# MMCSD8_MMC_CTLCFG_0FA00000h register map
Vendor: Texas Instruments
Registers are 16-bit, read-write, reset 0x0 unless marked. A register's access mark holds for its fields unless they carry their own. Offsets are as the file gives them; [hi:lo] are bit positions; {n}, {i} and the like mark numbered series; 'fields as' and 'values as' point back to an identical list.

## mmc_ctlcfg (part 3 of 4)
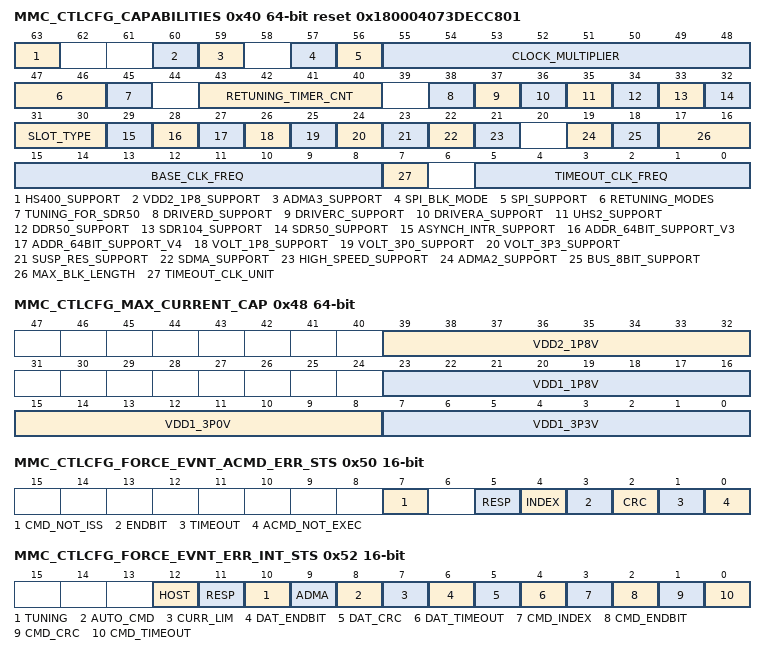
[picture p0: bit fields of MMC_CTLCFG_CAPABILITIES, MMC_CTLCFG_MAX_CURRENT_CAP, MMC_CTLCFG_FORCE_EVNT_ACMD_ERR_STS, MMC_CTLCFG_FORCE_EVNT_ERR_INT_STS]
0x40 MMC_CTLCFG_CAPABILITIES 64-bit ro reset 0x180004073DECC801 — This register provides the HD with information specific to the HC implementation. The HC may implement these values as fixed or loaded from flash memory during power on initialization.
  [63] HS400_SUPPORT — 1 HS400 is Supported 0 HS400 is Not Supported 0 HS400 Mode is not Supported1 HS400 Mode is Supported
  [60] VDD2_1P8_SUPPORT — This field indicates that support of VDD2 on Host system. 0 1.8V VDD2 is not Supported1 1.8V VDD2 is Supported
  [59] ADMA3_SUPPORT — This field indicates that support of ADMA3 on Host Controller. 0 ADMA3 is not Supported1 ADMA3 is Supported
  [57] SPI_BLK_MODE — This field indicates whether SPI Block Mode is supported or not. 0 SPI Block Mode is not Supported1 SPI Block Mode is Supported
  [56] SPI_SUPPORT — This field indicates whether SPI Mode is supported or not. 0 SPI Mode is not Supported1 SPI Mode is Supported
  [55:48] CLOCK_MULTIPLIER — This field indicates clock multiplier value of programmable clock generator. Refer to Clock Control register. Setting 00h means that Host Controller does not support programmable clock generator. 'FF' Clock Multiplier M = 256 --------- '02' Clock Multiplier M = 3 '01' Clock Multiplier M = 2 '00' Clock Multiplier is Not Supported. Reset Source: vbus_amod_g_rst_n
  [47:46] RETUNING_MODES — This field defines the re-tuning capability of a Host Controller and how to manage the data transfer length and a Re-Tuning Timer by the Host Driver. '00' Mode 1 '01' Mode 2 '10' Mode 3 '11' Reserved.There are two re-tuning timings:Re-Tuning Request and expiration of a Re-Tuning Timer. By receiving either timing, the Host Driver executes the re-tuning procedure just before a next command issue. 0 Mode 11 Mode 22 Mode 33 Reserved
  [45] TUNING_FOR_SDR50 — If this bit is set to 1, this Host Controller requires tuning to operate SDR50. [Tuning is always required to operate SDR104]. '0' '1' 0 SDR50 does not require tuning1 SDR50 requires tuning
  [43:40] RETUNING_TIMER_CNT — This field indicates an initial value of the Re-Tuning Timer for Re-Tuning Mode 1 to 3. 0h - Get information via other source 1h = 1 seconds 2h = 2 seconds 3h = 4 seconds 4h = 8 seconds ------ n = 2[n-1] seconds ------ Bh = 1024 seconds Fh - Ch = Reserved Reset Source: vbus_amod_g_rst_n
  [38] DRIVERD_SUPPORT — This bit indicates support of Driver Type D for 1.8 Signaling. '0' Driver Type D is Not supported, '1' Driver Type D is supported 0 Driver Type D is not Supported1 Driver Type D is Supported
  [37] DRIVERC_SUPPORT — This bit indicates support of Driver Type C for 1.8 Signaling. '0' Driver Type C is Not supported, '1' Driver Type C is supported 0 Driver Type C is not Supported1 Driver Type C is Supported
  [36] DRIVERA_SUPPORT — This bit indicates support of Driver Type A for 1.8 Signaling. '0' Driver Type A is Not supported, '1' Driver Type A is supported 0 Driver Type A is not Supported1 Driver Type A is Supported
  [35] UHS2_SUPPORT — This bit indicates whether Host controller supports UHS-II. If this bit is set to 1, 1.8V VDD2 Support shall be set to 1 [Host Sys- tem shall support VDD2 power supply]. 1 UHS-II is Supported 0 UHS-II is Not Supported 0 UHS-II is not Supported1 UHS-II is Supported
  [34] DDR50_SUPPORT — This bit indicates whether DDR50 is supported or not. 0 DDR50 is not Supported1 DDR50 is Supported
  [33] SDR104_SUPPORT — This bit indicates whether SDR104 is supported or not.SDR104 requires tuning. 0 SDR104 is not Supported1 SDR104 is Supported
  [32] SDR50_SUPPORT — If SDR104 is supported, this bit shall be set to 1. Bit 40 indicates whether SDR50 requires tuning or not. 0 SDR50 is not Supported1 SDR50 is Supported
  [31:30] SLOT_TYPE — This field indicates usage of a slot by a specific Host System. [A host controller register set is defined perslot.] Embedded slot for one device [01b] means that only one non-removable device is connected to a SD bus slot. Shared Bus Slot [10b] can be set if Host Controller supports Shared Bus Control register. The Standard Host Driver controls only a removable card or one embedded device is connected to a SD bus slot. If a slot is configured for shared bus [10b], the Standard Host Driver does not control embedded devices connected to a shared bus. Shared bus slot is controlled by a specific host driver developed by a Host System. 0 Removeable Card Slot1 Embedded Slot for One Device2 Shared Bus Slot (SD Mode)3 Reserved
  [29] ASYNCH_INTR_SUPPORT — Refer to SDIO Specification Version 3.00 about asynchronous interrupt. 0 Asynchronous Interrupt not Supported1 Asynchronous Interrupt Supported
  [28] ADDR_64BIT_SUPPORT_V3 — IMeaning of this bit is different depends on Versions [Refer to Table 2-35 for more details]. Host Controller Version 3.00 and Ver4.10 use this bit as 64-bit System Address support for V3 mode. Host Con- troller Version 4.00 uses this bit as 64-bit System Address support for both V3 and V4 modes. SDMA cannot be used in 64-bit Address-ing in Version 3 mode. If this bit is set to 1, 64-bit ADMA2 with using 96-bit Descriptor may be enabled as follows: In case of Host Controller Version 3, 64-bit ADMA2 is enabled by DMA Select =11b in the Host Control 1 register. In case of Host Controller Version 4, 64-bitADMA2 for Version 3 is enabled by setting Host Version 4 Enable =0 and DMA Select = 11b. 1 - 64-bit System Address for V3 is Supported 0 - 64-bit System Address for V3 is not Supported 0 64-bit System Address for V3 is not Supported1 64-bit System Address for V3 is Supported
  [27] ADDR_64BIT_SUPPORT_V4 — This bit is added from Version 4.10. Set-ting 1 to this bit indicates that the Host Controller supports 64-bit System Addressing of Version 4 mode [Refer to Table 2-35 for the summary of 64-bit sys-tem address support].. When this bit is set to 1, full or a part of 64-bit address should be used to decode Host Controller Registers so that Host Controller Registers can be placed above system memory area. 64-bit address decode of Host Controller Registers is effective regardless of setting to 64bit Addressing in Host Control 2. If this bit is set to 1, 64-bit DMA Address-ing for Version 4 is enabled by setting Host Version 4 Enable =1, 64-bit Address-ing =1 in the Host Control 2 register.SDMA can be used and ADMA2 uses 128-bit Descriptor. 0 64-bit System Address for V4 is not Supported1 64-bit System Address for V4 is Supported
  [26] VOLT_1P8_SUPPORT — This bit indicates whether the HC supports 1.8V. 0 1.8V Not Supported1 1.8V Supported
  [25] VOLT_3P0_SUPPORT — This bit indicates whether the HC supports 3.0V. 0 3.0V Not Supported1 3.3V Supported
  [24] VOLT_3P3_SUPPORT — This bit indicates whether the HC supports 3.3V. 0 3.3V Not Supported1 3.3V Supported
  [23] SUSP_RES_SUPPORT — This bit indicates whether the HC supports Suspend / Resume functionality. If this bit is 0, the Suspend and Resume mechanism are not supported and the HD shall not issue either Suspend / Resume commands. 0 Suspend and Resume mechanism Not Supported1 Suspend and Resume mechanism Supported
  [22] SDMA_SUPPORT — This bit indicates whether the HC is capable of using DMA to transfer data between system memory and the HC directly.Version 4.10 Host Controller shall support SDMA if ADMA2 is supported. 0 SDMA Not Supported1 SDMA Supported
  [21] HIGH_SPEED_SUPPORT — This bit indicates whether the HC and the Host System support High Speed mode and they can supply SD Clock frequency from 25Mhz to 50 Mhz [for SD]/ 20MHz to 52MHz [for MMC]. 0 High Speed Not Supported1 High Speed Supported
  [19] ADMA2_SUPPORT — '0' ADMA2 Not Supported '1' ADMA2 Supported 0 ADMA2 Not Supported1 ADMA2 Supported
  [18] BUS_8BIT_SUPPORT — This bit indicates whether the Host Controller is capable of using 8-bit bus width mode. This bit is not effective when Slot Type is set to 10b. In this case, refer to Bus Width Preset in the Shared Bus resister. 0 Extended Media Bus Not Supported1 Extended Media Bus Supported
  [17:16] MAX_BLK_LENGTH — This value indicates the maximum block size that the HD can read and write to the buffer in the HC. The buffer shall transfer this block size without wait cycles. Three sizes can be defined as indicated below. 0 512 byte1 1024 byte2 2048 byte3 4096 byte
  [15:8] BASE_CLK_FREQ — [1]6-bit Base Clock Frequency: This mode is supported by the Host Controller Version 1.00 and 2.00. Upper 2-bit is not effective and always 0. Unit values are 1MHz. The supported clock range is 10MHz to 63MHz. '11xx xxxxb' Not Supported '0011 1111b' 63MHz '0000 0010b' 2MHz '0000 0001b' 1MHz '0000 0000b'Get Information via another method [2]8-bit Base Clock Frequency: This mode is supported by the Host Controller Version 3.00.Unit values are 1MHz. The supported clock range is 10MHz to 255MHz. 'FFh' 255MHz '02h' 2MHz '01h' 1MHz '00h' Get Information via another method.If the real frequency is 16.5MHz, the lager value shall be set 0001 0001b [17MHz] because the Host Driver use this value to calculate the clock divider value [Refer to the SDCLK Frequency Select in the Clock Control register.] and it shall not exceed upper limit of the SD Clock frequency. If these bits are all 0, the Host System has to get information via another method. Reset Source: vbus_amod_g_rst_n
  [7] TIMEOUT_CLK_UNIT — This bit shows the unit of base clock frequency used to detect Data Timeout Error. 0 KHz1 MHz
  [5:0] TIMEOUT_CLK_FREQ — This bit shows the base clock frequency used to detect Data Timeout Error. '000000' Get Information via another method, 'not 0' 1KHz to 63KHz/1MHz to 63MHz Reset Source: vbus_amod_g_rst_n
0x48 MMC_CTLCFG_MAX_CURRENT_CAP 64-bit ro — This register indicates maximum current capability for each voltage
  [39:32] VDD2_1P8V — Maximum Current for 1.8V VDD2 Reset Source: vbus_amod_g_rst_n
  [23:16] VDD1_1P8V — Maximum Current for 1.8V VDD1 Reset Source: vbus_amod_g_rst_n
  [15:8] VDD1_3P0V — Maximum Current for 3.0V VDD1 Reset Source: vbus_amod_g_rst_n
  [7:0] VDD1_3P3V — Maximum Current for 3.3V VDD1 Reset Source: vbus_amod_g_rst_n
0x50 MMC_CTLCFG_FORCE_EVNT_ACMD_ERR_STS wo — This register is not physically implemented, rather it is an address where Auto CMD Error Status register can be written. Writing 1 : set each bit of the Auto CMD12 Error Status Register Writing 0 : no effect.
  [7] CMD_NOT_ISS — Force Event for Command Not Issued by AUTO CMD12 Error. 0 No Interrupt1 Interrupt is generated
  [5] RESP — Force Event for AUTO CMD Response Error.. 0 No Interrupt1 Interrupt is generated
  [4] INDEX — Force Event for AUTO CMD Index Error.. 0 No Interrupt1 Interrupt is generated
  [3] ENDBIT — Force Event for AUTO CMD End Bit Error. 0 No Interrupt1 Interrupt is generated
  [2] CRC — Force Event for AUTO CMD Timeout Error. 0 No Interrupt1 Interrupt is generated
  [1] TIMEOUT — Force Event for AUTO CMD Timeout Error. 0 No Interrupt1 Interrupt is generated
  [0] ACMD_NOT_EXEC — Force Event for AUTO CMD12 Not Executed. 0 No Interrupt1 Interrupt is generated
0x52 MMC_CTLCFG_FORCE_EVNT_ERR_INT_STS wo — This register is not physically implemented, rather it is an address where Error Interrupt Status register can be written.
  [12] HOST — Force Event for Host Error 0 No Interrupt1 Interrupt is generated
  [11] RESP — Force Event for Response Error 0 No Interrupt1 Interrupt is generated
  [10] TUNING — Force Event for Tuning Error. 0 No Interrupt1 Interrupt is generated
  [9] ADMA — Force Event for ADMA Error. 0 No Interrupt1 Interrupt is generated
  [8] AUTO_CMD — Force Event for Auto CMD Error. 0 No Interrupt1 Interrupt is generated
  [7] CURR_LIM — Force Event for Current Limit Error. 0 No Interrupt1 Interrupt is generated
  [6] DAT_ENDBIT — Force Event for Data End Bit Error. 0 No Interrupt1 Interrupt is generated
  [5] DAT_CRC — Force Event for Data CRC Error. 0 No Interrupt1 Interrupt is generated
  [4] DAT_TIMEOUT — Force Event for Data Timeout Error. 0 No Interrupt1 Interrupt is generated
  [3] CMD_INDEX — Force Event for Command Index Error 0 No Interrupt1 Interrupt is generated
  [2] CMD_ENDBIT — Force Event for Command End Bit Error. 0 No Interrupt1 Interrupt is generated
  [1] CMD_CRC — Force Event for Command CRC Error. 0 No Interrupt1 Interrupt is generated
  [0] CMD_TIMEOUT — Force Event for CMD Timeout Error. 0 No Interrupt1 Interrupt is generated
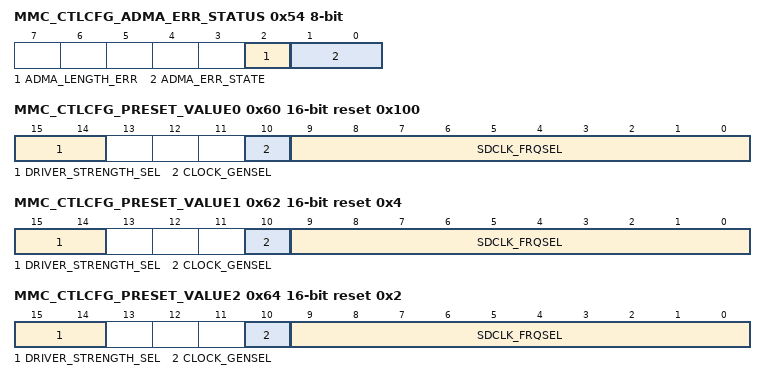
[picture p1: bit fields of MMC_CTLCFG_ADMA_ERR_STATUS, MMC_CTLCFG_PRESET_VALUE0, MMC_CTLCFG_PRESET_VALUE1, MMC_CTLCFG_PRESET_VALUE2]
0x54 MMC_CTLCFG_ADMA_ERR_STATUS 8-bit ro — When the ADMA Error interrupt occur, this register holds the ADMA State in ADMA Error States field and ADMA System Address holds address around the error descriptor
  [2] ADMA_LENGTH_ERR — This error occurs in the following 2 cases.While Block Count Enable being set, the total data length specified by the Descriptor table is different from that specified by the Block Count and Block Length. Total data length can not be divided by the block length. 0 No Error1 Error set
  [1:0] ADMA_ERR_STATE — This field indicates the state of ADMA when error is occurred during ADMA data transfer. This field never indicates '10' because ADMA never stops in this state. D01 D00 : ADMA Error State when error occurred Contents of SYS_SDR register. 0 ST_STOP(Stop DMA) Points to next of the error descriptor1 ST_FDS(Fetch Descriptor)Points to the error descriptor2 Never set this state(Not Used)3 ST_TFR(Transfer Data) Points to the next of the error descriptor
0x58 MMC_CTLCFG_ADMA_SYS_ADDRESS 64-bit — This register contains the physical address used for ADMA data transfer
  [63:0] ADMA_ADDR — The 32-bit addressing Host Driver uses lower 32-bit of this register [upper 32-bit should be set to 0] and shall program Descriptor Table on 32-bit boundary andset 32-bit boundary address to thisregister. DMA2/3 ignores lower 2-bit of this register and assumes it to be 00b. DMA in 64-bit addressing. The 64-bit addressing Host Driver uses all bits of this register and shall program Descriptor Table on 64-bit boundary and set 64-bit boundary address to this register. DMA2/3 ignores lower 3-bit of this register andassumes it to be 000b. SDMA If Host Version 4.00 Enable is set to 1, SDMA use this register to indicate System Address of data location instead of using SDMA System Address register [Offset 003-000h]. SDMA can be used in32-bit and 64-bit addressing in Version 4.00. ADMA2 This register holds byte address of executing command of the Descriptor table. At the start of ADMA2, the Host Driver shall set start address of the Descriptor table. The ADMA increments thisregister address, which points to next line, when every fetching a Descriptor line. When the ADMA Error Interrupt is generated, this register shall hold the Descriptor address depending on the ADMA state. ADMA3 This register is set by ADMA3. Host Driver is not necessary to set this register. The ADMA3 increments address of this register,which points to next line, when every time fetching a Descriptorline. When Error Interrupt is generated, this register shall hold the Descriptor address depending on the ADMA state. Register Value - 00000000_xxxxxxxxh Addressing Mode - 32-bit System Address Register Value - xxxxxxxx_xxxxxxxxh Addressing Mode - 64-bit System Address Reset Source: vbus_amod_g_rst_n
0x60 MMC_CTLCFG_PRESET_VALUE0 ro reset 0x100 — This register is used to read the SDCLK Frequency Select Value,Clock Generator Select Value,Driver Strength Select Value
  [15:14] DRIVER_STRENGTH_SEL — Driver Strength is supported by 1.8V signaling bus speed modes. This field is meaningless for 3.3V signaling. 0 Driver Type B is Selected1 Driver Type A is Selected2 Driver Type C is Selected3 Driver Type D is Selected
  [10] CLOCK_GENSEL — This bit is effective when Host Controller supports programmable clock '0' Host Controller Ver2.00 Compatible Clock Generator '1' Programmable Clock Generator Reset Source: vbus_amod_g_rst_n
  [9:0] SDCLK_FRQSEL — 10-bit preset value to set SDCLK Frequency Select in the Clock Control Register is described by a host system. Reset Source: vbus_amod_g_rst_n
0x62 MMC_CTLCFG_PRESET_VALUE1 ro reset 0x4 — This register is used to read the SDCLK Frequency Select Value,Clock Generator Select Value,Driver Strength Select Value
  fields as MMC_CTLCFG_PRESET_VALUE0
0x64 MMC_CTLCFG_PRESET_VALUE2 ro reset 0x2 — This register is used to read the SDCLK Frequency Select Value,Clock Generator Select Value,Driver Strength Select Value
  fields as MMC_CTLCFG_PRESET_VALUE0
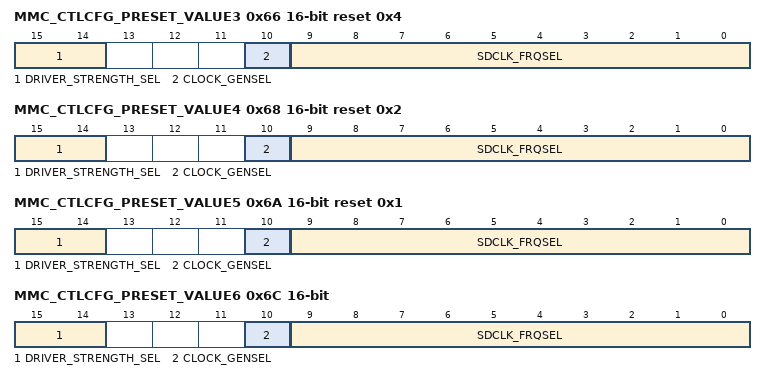
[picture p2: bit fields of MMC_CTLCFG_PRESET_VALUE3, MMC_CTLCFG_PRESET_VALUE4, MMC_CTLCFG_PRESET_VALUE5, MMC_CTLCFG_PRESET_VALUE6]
0x66 MMC_CTLCFG_PRESET_VALUE3 ro reset 0x4 — This register is used to read the SDCLK Frequency Select Value,Clock Generator Select Value,Driver Strength Select Value
  fields as MMC_CTLCFG_PRESET_VALUE0
0x68 MMC_CTLCFG_PRESET_VALUE4 ro reset 0x2 — This register is used to read the SDCLK Frequency Select Value,Clock Generator Select Value,Driver Strength Select Value
  fields as MMC_CTLCFG_PRESET_VALUE0
0x6A MMC_CTLCFG_PRESET_VALUE5 ro reset 0x1 — This register is used to read the SDCLK Frequency Select Value,Clock Generator Select Value,Driver Strength Select Value
  fields as MMC_CTLCFG_PRESET_VALUE0
0x6C MMC_CTLCFG_PRESET_VALUE6 ro — This register is used to read the SDCLK Frequency Select Value,Clock Generator Select Value,Driver Strength Select Value
  fields as MMC_CTLCFG_PRESET_VALUE0
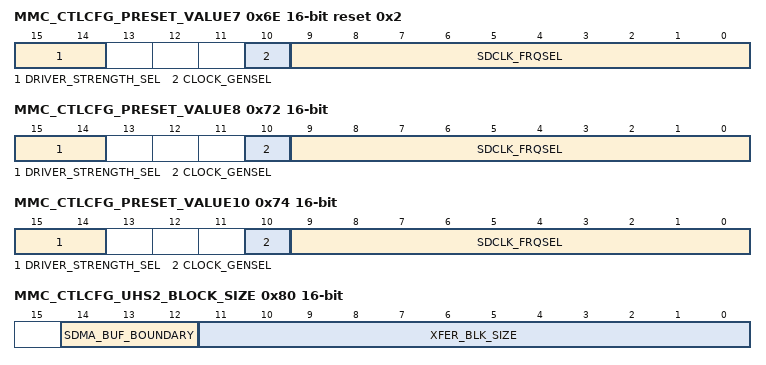
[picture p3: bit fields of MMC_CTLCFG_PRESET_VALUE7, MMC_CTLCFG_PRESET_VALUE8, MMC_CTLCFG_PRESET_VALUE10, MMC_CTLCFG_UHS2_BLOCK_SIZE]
0x6E MMC_CTLCFG_PRESET_VALUE7 ro reset 0x2 — This register is used to read the SDCLK Frequency Select Value,Clock Generator Select Value,Driver Strength Select Value
  fields as MMC_CTLCFG_PRESET_VALUE0
0x72 MMC_CTLCFG_PRESET_VALUE8 ro — This register is used to read the SDCLK Frequency Select Value,Clock Generator Select Value,Driver Strength Select Value
  fields as MMC_CTLCFG_PRESET_VALUE0
0x74 MMC_CTLCFG_PRESET_VALUE10 ro — This register is used to read the SDCLK Frequency Select Value,Clock Generator Select Value,Driver Strength Select Value
  fields as MMC_CTLCFG_PRESET_VALUE0
0x78 MMC_CTLCFG_ADMA3_DESC_ADDRESS 64-bit — The start address of Integrated DMA Descriptor is set to this register.
  [63:0] INTG_DESC_ADDR — The start address of Integrated DMA Descriptor is set to this register. Writing to a specific address starts ADMA3 depends on 32-bit/64-bit address-ing. The ADMA3 fetches one Descriptor Address and increments this field to indicate the next Descriptor address. The 32-bit addressing Host Driver uses lower 32- bit of this register and shall program Descriptor Table on 32-bit boundary.ADMA3 ignores lower 2-bit of this register and assumes it to be 00b. Writing to 07Bh starts ADMA3 data transfer. The 64-bit addressing Host Driver uses all 64-bit of this register and shall program Descriptor Table on 64-bit boundary. ADMA3 ignores lower 3-bit of this register and assumes it to be 000b. Writing to 07Fh starts ADMA3 data transfer. Register Value- 00000000_xxxxxxxxh Addressing Mode - 32-bit System Address Register Value - xxxxxxxx_xxxxxxxxh Addressing Mode - 64-bit System Address Reset Source: vbus_amod_g_rst_n
0x80 MMC_CTLCFG_UHS2_BLOCK_SIZE — This register is used to configure the number of bytes in a data block
  [14:12] SDMA_BUF_BOUNDARY — When system memory is managed by paging, SDMA data transfer is performed in unit of paging. A page size of sys-tem memory management is set to this field. Host Controller generates the DMA Interrupt at the page boundary and requests the Host Driver to update the ADMA System Address register. SDMA waits until the ADMA System Address register is written. At the end of transfer, the Host Controller may issue or may not issue DMA Interrupt. In particular, DMA Interrupt shall not be issued after Transfer Complete Interrupt is issued. These bits shall be supported when the SDMA Support in the Capabilities register is set to 1 and this function is active when the DMA Enable in the UHS-II Transfer Mode register is set to 1. ADMA does not use this field. 0 4K Bytes1 8K Bytes2 16K Bytes3 32K Bytes4 64K Bytes5 128K Bytes6 256K Bytes7 512K Bytes
  [11:0] XFER_BLK_SIZE — This register specifies the block size of data packet. SD Memory Card uses a fixed block size of 512 bytes. Vari-able block size may be used for SDIO. The maximum value is 2048 Bytes because CRC16 covers up to 2048 bytes. This register is effective when Data Present is set to 1 in UHS-II Command register. 0 No data transfer1 1 Byte2 2 Bytes512 512 Bytes2048 2048 Bytes
0x84 MMC_CTLCFG_UHS2_BLOCK_COUNT 32-bit — This register is used to configure the number of data blocks
  [31:0] XFER_BLK_COUNT — This register is effective when Data Present is set to 1 in UHS-II Command register and is enabled when Block Count Enable is set to 1 and Block / Byte Mode is set to 0 in the UHS-IITransfer Mode register. Data transfer stops when the count reaches zero. Setting the block count to 0 results in no data blocks is transferred. This register should be accessed only when no transaction is executing [i.e.,after transactions are stopped]. During data transfer, read operations on this register may return an invalid value and write operations are ignored. 00000000h - Stop Count 00000001h - 1 block 00000002h - 2 blocks ..... ..... FFFFFFFFh - 4G blocks -1. 0 Stop Count1 1 block2 2 blocks3 3 blocks42949 4G blocks -167295
0x88 MMC_CTLCFG_UHS2_COMMAND_PKT_j 8-bit — UHS-II Command Packet image is set to this register. The maximum length is 20 bytes. The command length varies depends on a Command Packet type. The length is specified by the UHS-II Command register.
  [7:0] CMD_PKT_BYTE — UHS-II Command Packet image is set to this register.The command length varies depends on a Command Packet type. Reset Source: vbus_amod_g_rst_n
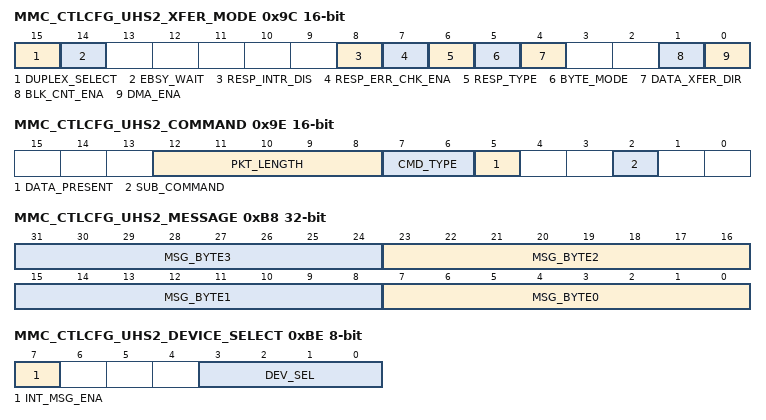
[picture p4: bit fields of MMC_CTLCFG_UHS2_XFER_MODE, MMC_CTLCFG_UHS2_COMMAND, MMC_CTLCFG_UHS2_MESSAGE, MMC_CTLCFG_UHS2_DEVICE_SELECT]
0x9C MMC_CTLCFG_UHS2_XFER_MODE — This register is used to control the operations of data transfers
  [15] DUPLEX_SELECT — Use of 2 lane half duplex mode is determined by Host Driver. 0 Full Duplex Mode1 Half Duplex Mode
  [14] EBSY_WAIT — This bit is set when issuing a command which is accompanied by EBSY packet to indicate end of command execution. Busy is expected for CCMD with R1b/R5b type and DCMD with data transfer.If this bit is set to 1, Host Controller waits receiving of EBSY packet and on receiving EBSY packet, Transfer Com-plete in the Normal Interrupt Status reg-ister is set to 1 to indicate end ofbusy. If an error is indicated in EBSY packet [ex. Memory Error], EBSY Error in the UHS-II Error Interrupt Status register is set to 1. Setting of EBSY Error also sets Error Interrupt to 1 in the Normal Inter-rupt Status register. Error Interrupt and Transfer Complete shall be set together. '1' Wait EBSY, '0' Issue a command without busy. Reset Source: vbus_amod_g_rst_n
  [8] RESP_INTR_DIS — Host Controller Version 4.00 supports response error check function to avoid overhead of response error check by Host Driver. Only R1 or R5 can be checked. If Host Driver checks response error, sets this bit to 0 and waits Command Complete Interrupt and then check the response register. If Host Controller checks response error, sets this bit to 1 and sets Response Error Check Enable to 1. Command Complete Interrupt is disabled by this bit regardless of Com-mand Complete Signal Enable. 0 Enable Response Interrupt1 Disable Response Interrupt
  [7] RESP_ERR_CHK_ENA — Host Controller Version 4.00 supports response error check function to avoid overhead of response error check by Host Driver.Only R1 or R5 can be checked. If Host Driver checks response error, this bit is set to 0 and Response Inter-rupt Disable is set to 0. If Host Control-ler checks response error, sets this bit to 1 and sets Response Interrupt Dis-able to 1. Response Type R1 / R5 selects either R1 or R5 response type. If an error is detected, RES Packet Error Interrupt is generated in the UHS-II Error Interrupt Status register. 0 Disable Response Error Check1 Enable Response Error Check
  [6] RESP_TYPE — When response error check is enabled, this bit selects either R1 or R5 response types. Two types of response checks are supported: R1 for memory and R5 for SDIO. Error Statuses Checked in R1 Bit31 OUT_OF_RANGE Bit30 ADDRESS_ERROR Bit29 BLOCK_LEN_ERROR Bit26 WP_VIOLATION Bit25 CARD_IS_LOCKED Bit23 COM_CRC_ERROR Bit21 CARD_ECC_FAILED Bit20 CC_ERROR Bit19 ERROR Response Flags Checked in R5 .Bit07 COM_CRC_ERROR .Bit03 ERROR .Bit01 FUNCTION_NUMBER .Bit00 OUT_OF_RANGE 0 Memory1 SDIO
  [5] BYTE_MODE — This bit specifies whether data transfer is in byte mode or block mode when Data Present is set to 1. This bit is effective to a command with data trans-fer. 0 Block Mode1 Byte Mode
  [4] DATA_XFER_DIR — This bit specifies direction of data trans-fer when Data Present is set to 1. This bit is effective to a command with data transfer. 0 - Read [Card to Host] 1 - Write [Host to Card] 0 Read from Card to Host1 Write from Host to Card
  [1] BLK_CNT_ENA — This bit specifies whether data transfer usesUHS-II Block Count register. If this bit is set to 1, data transfer is terminated by Block Count. Setting to UHS-II Block Count register shall be equivalent to TLEN in UHS-II Command Packet reg-ister. 0 Disable Block count1 Enable Block count
  [0] DMA_ENA — This bit selects whether DMA is used or not and is effective to a command with data transfer. One of DMA types is selected by DMA Select in the Host Control 1 register. 0 DMA mode is Disabled1 DMA mode is Enabled
0x9E MMC_CTLCFG_UHS2_COMMAND — This register is used to program the Command for host controller
  [12:8] PKT_LENGTH — A command packet length, which is set in the UHS-II Command Packet register, is set to this register. 00011b - 00000b - 3-0 Bytes [Not used] 00100b - 4 Bytes .......... ...... 10100b - 20 Bytes 11111b 10101b Reset Source: vbus_amod_g_rst_n
  [7:6] CMD_TYPE — This field is used to distinguish a spe-cific command like abort command. If this field is set to 00b, the UHS-II RES Packet is stored in UHS-II Response register [0B3h-0A0h]. To avoid overwrit-ing the UHS-II Response register, when this filed is set to 01b, the RES Packet [4 bytes length] of TRANS_ABORT CCMD is stored in the Response regis-ter [013h-010h] and when this filed is set to 10b, the RES Packet [8 byteslength] of memory or SDIO abort com-mand [CMD12 or SDIO Abort com-mand] is stored in the Response register [01Fh-018h]. When this filed is set to 11b, Host Controller controls lane to go into dormant state. '00' Normal Command '01' TRANS_ABORT CCMD '10' CMD12 or SDIO Abort Command '11' Go Dormant Command 0 Normal command1 TRANS_ABORT CCMD2 Abort command3 Go dormant command
  [5] DATA_PRESENT — This bit specifies whether the command is accompanied by data packet. 0 Data not Present1 Data present
  [2] SUB_COMMAND — This bit is added from Version 4.10 to distinguish a main command or sub command [Refer to Section 1.17].When issuing a main command, this bitis set to 0 and when issuing a sub com-mand, this bit is set to 1. Setting of this bit is checked by Sub Command Status in the Present State register. 0 Main Command1 Sub Command
0xA0 MMC_CTLCFG_UHS2_RESPONSE_j 8-bit ro — This register is used to store received UHS-II RES Packet image
  [7:0] RESP_PKT_BYTE — Host Controller saves received UHS-II RES Packet image to this register except the response of an abort command. Reset Source: vbus_amod_g_rst_n
0xB4 MMC_CTLCFG_UHS2_MESSAGE_SELECT 8-bit — This register is used to access internal buffer
  [1:0] MSG_SEL — Host Controller holds 4 MSG packets in FIFO buffer.One of 4 MSGs can be read from the UHS-II MSG register [0BB-0B8h] by setting this register.[Assumed for debug usage.] '00' The latest MSG '01' One MSG before '10' Two MSGs before '11' Three MSGs before Reset Source: vbus_amod_g_rst_n
0xB8 MMC_CTLCFG_UHS2_MESSAGE 32-bit ro — This register is used to access internal buffer
  [8n+7:8n] MSG_BYTE{n} (n=0..3) — Host Controller holds 4 MSG packets in FIFO buffer. One of 4 MSGs [length is 4 bytes] can be read fromthis register by setting UHS-II MSG Select register. Usually 2 duplicate MSG packets are sent from/toUHS-II card. One of these 2 MSG packets which Host Controller recognizes as valid one is stored in theUHS-II MSG Register. Reset Source: vbus_amod_g_rst_n
0xBC MMC_CTLCFG_UHS2_DEVICE_INTR_STATUS access not given — This register shows receipt of INT MSG from which device
  [15:0] DEV_INT_STS — This register shows receipt of INT MSG from which device and is effective when INT MSG Enable is set to 1 in the UHS- II Device Select register. On receiving INT MSG from a device, Host Controller saves the INT MSG to UHS-II Device Interrupt Code register. A bit of this register, which is corre- spondent to Device ID, is set to 1 and generate Card Interrupt in Normal Interrupt Status register. Writing a bit to 1 clears the status bit [interrupt is treated] and Writing a bit to 0 keeps the status value [interrupt is untreated]. If INT MSG Enable is set to 0, this register is cleared to 0 and Host Controller ignores receipt of INT MSG. Effective bit range of this register is determined by Number of Devices Supported in the UHS-II General Capabilities regis-ter. If N devices are supported, bits 1 to N are effective. Then Device ID is supposed to be assigned from 1 sequentially at the UHS-II Initialization. A bit of unsupported Device ID in this register shall be indicated to 0. D00 - Not used [Reserved] D01 - Setting 1 means INT MSG is received from Device ID 1 D02 - Setting 1 means INT MSG is received from Device ID 2 .... ..... D15 - Setting 1 means INT MSG is received from Device ID 15 Reset Source: vbus_amod_g_rst_n (access R/W1TC)
0xBE MMC_CTLCFG_UHS2_DEVICE_SELECT 8-bit — UHS-II Device Select Register
  [7] INT_MSG_ENA — This bit enables receipt of INT MSG. If this bit is set to 1,receipt of INT MSG is informed by Card Interrupt in the Nor-mal Interrupt Status register. If this bit is set to 0, Host Con-troller ignores receipt of INT MSG and may not set the UHS-II Device Interrupt Code register. Support of INT MSG Interrupt is optional. If trying to set this bit to 1 but still this bit is read 0, INT MSG Interrupt is not sup-ported by the Host Controller. In this case, UHS-II Device Interrupt Status register always shall be read 0 and UHS-II Device Interrupt Code register may not be implemented. '0' Disabled '1' Enabled Reset Source: vbus_amod_g_rst_n
  [3:0] DEV_SEL — Host Controller holds an INT MSG packet per device. One of INT MSGs [up to 15] can be selected by this field and read from the UHS-II Device Interrupt Code Register [0BFh]. This field is effective when INT MSG Enable is set to 1. The number of devices implemented in the Host Controller is indicated by Number of Devices supported in the UHS-II General Capabilities register. 0h Unselected [Default] 1h INT MSG of Device ID 1 is selected 2h INT MSG of Device ID 2 is selected ..... ..... Fh INT MSG of Device ID 15 is selected Reset Source: vbus_amod_g_rst_n
0xBF MMC_CTLCFG_UHS2_DEVICE_INT_CODE 8-bit ro — This register is effective when INT MSG Enable is set to 1 in the UHS-II Device Select register.
  [7:0] DEV_INTR — This register is effective when INT MSG Enable is set to 1 in the UHS-II Device Select register. Host Controller holds an INT MSG packet per device. One of INT MSGs [Code length is 1 byte] up to 15 can be read from this register by select-ing UHS-II Device Select. The number of the registers to hold INT MSGs is determined by Number of Devices Sup-ported in the UHS-II General Capabili-ties register. Device ID is supposed to be assigned from 1 sequentially at the UHS-II Initialization. Reset Source: vbus_amod_g_rst_n
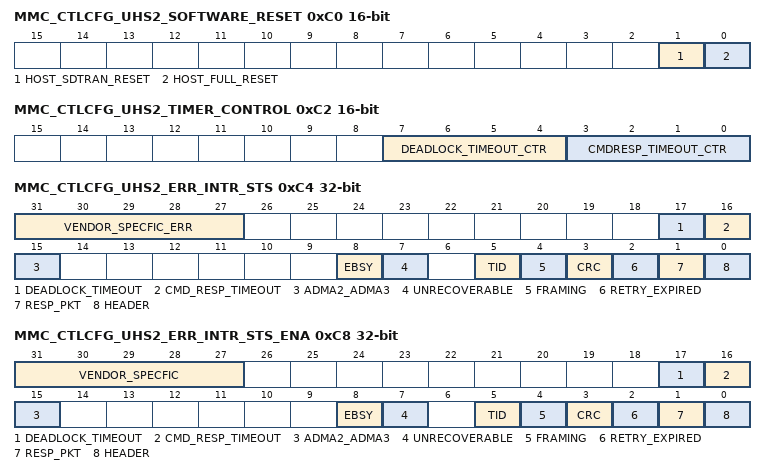
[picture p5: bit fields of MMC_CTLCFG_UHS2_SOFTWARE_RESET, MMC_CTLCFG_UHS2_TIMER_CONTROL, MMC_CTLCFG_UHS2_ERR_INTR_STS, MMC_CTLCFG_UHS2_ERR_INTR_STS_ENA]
0xC0 MMC_CTLCFG_UHS2_SOFTWARE_RESET — UHS-II Software Reset Register
  [1] HOST_SDTRAN_RESET — Host Driver set this bit to 1 to reset SD-TRAN layer when CMD0 is issued to Device or data transfer error occurs. This bit is cleared automatically at completionof SD-TRAN reset. If CMD0 is issued, SD-TRAN Initial- ization sequence from CMD8 is required to use UHS-II mode. Assuming that bus power is maintained and CM-TRAN Initialization is not required. '0' Not Affected '1' Reset SD TRAN Host Controller requires to do followings: [1] SD Clock Enable is maintained.[Continue to provide RCLK]. [2] All setting register is maintained. [3] Internal sequencers are reset to just after power on.be able to issue a command. [4] All Interrupt Status, Status Enable and Signal Enable are cleared. [5] Data transfer is terminated and data in buffer is dis-carded. 0 Not Affected1 Reset SDTRAN
  [0] HOST_FULL_RESET — On issuing FULL_RESET CCMD, Host Driver set this bit to 1 to reset Host Controller. This bit is cleared auto-matically at completion of Host Controller reset. Initial-ization sequence from PHY Initialization is required to use UHS-II mode. Assuming that bus power is maintained. Host Controller requires to do followings: [1] SD Clock Enable is cleared. [Internal Clock is still synchronized]. [2] All setting register is cleared. [3] Internal sequencers are reset to just after power on. [4] All Interrupt Status, Status Enable and Signal Enable are cleared. 0 Not Affected1 Reset Host Conroller
0xC2 MMC_CTLCFG_UHS2_TIMER_CONTROL — UHS-II Timeout Control Register
  [7:4] DEADLOCK_TIMEOUT_CTR — This value determines the deadlock period while host expecting to receive a packet [1 second]. Tim-eout clock frequency will be generated by dividing the base clock TMCLK value by this value. When setting this register, prevent inadvertent timeout events by clearing the Timeout for Deadlock [in the UHS-II Error Interrupt Status Enable register] 1111b Reserved 1110b TMCLK x 2^27 .............. .................. 0001b TMCLK x 2^14 0000b TMCLK x 2^13 Reset Source: vbus_amod_g_rst_n
  [3:0] CMDRESP_TIMEOUT_CTR — This value determines the interval between com-mand packet and response packet [5ms]. Timeout clock frequency will be generated by dividing the base clock TMCLK value by this value. When set-ting this register, prevent inadvertent timeout events by clearing the Timeout for CMD_RES [in the UHS-II Error Interrupt Status Enable register] 1111b Reserved 1110b TMCLK x 2^27 .............. .................. 0001b TMCLK x 2^14 0000b TMCLK x 2^13 Reset Source: vbus_amod_g_rst_n
0xC4 MMC_CTLCFG_UHS2_ERR_INTR_STS 32-bit access not given — This register gives the status of all UHS-II interrupts
  [31:27] VENDOR_SPECFIC_ERR — Vendor may use this field for vendor specific error status. '0' Interrupt is not generated '1' Vendor Specific Error Reset Source: vbus_amod_g_rst_n (access R/W1TC)
  [17] DEADLOCK_TIMEOUT — Setting of this bit means that deadlock timeout occurs. Host expects to receive a packet but not received in a specified timeout [1 second]. Timeout value is determined by the setting of Timeout Counter Value for Deadlock in UHS-II Timer Control register. 0 No Error1 Deadlock Error (access R/W1TC)
  [16] CMD_RESP_TIMEOUT — Setting of this bit means that RES Packet timeout occurs. Host expects to receive RES packet but not received in a specified timeout [5ms]. Timeout value is determined by the setting of Timeout Counter Value for CMD_RES in UHS-II Timer Control register. 0 No Error1 Resp packet timeout Error (access R/W1TC)
  [15] ADMA2_ADMA3 — Setting of this bit means that ADMA2/3 Error occurs in UHS-II mode. ADMA2/3 Error Status is indicated to the ADMA Error Status [054h], which is defined in the Host spec 3.00. 0 No Error1 ADMA2/3 Error (access R/W1TC)
  [8] EBSY — On receiving EBSY packet, if the packet indicates an error, this bit is set to 1. Setting of this bit also sets Error Interrupt and Transfer Completer together in the Normal Interrupt Status register. This error check is effective for a command with setting EBSY Wait in the UHS-II Transfer Mode register. 0 No Error1 EBSY Error (access R/W1TC)
  [7] UNRECOVERABLE — Setting of this bit means that Unrecoverable Error is set in a packet from a device. 0 No Error1 Device Unrecoverable Error (access R/W1TC)
  [5] TID — Setting of this bit means that TID Error occurs. 0 No Error1 TID Error (access R/W1TC)
  [4] FRAMING — Setting of this bit means that Framing Error occurs during a packet receiving. 0 No Error1 Framing Error (access R/W1TC)
  [3] CRC — Setting of this bit means that CRC Error occurs during a packet receiving. 0 No Error1 CRC Error (access R/W1TC)
  [2] RETRY_EXPIRED — Setting of this bit means that Retry Counter Expired Error occurs during data transfer.If this bit is set,either Framing Error or CRC Error in this register shall be set. 0 No Error1 Retry Expired Error (access R/W1TC)
  [1] RESP_PKT — Host Controller Version 4.00 supports response error check function to avoid overhead of response error check by Host Driver during DMA execution. If Response Error Check Enable is set to1 in the UHS- II Transfer Mode register, Host Controller Checks R1 or R5 response. If an error is detected in a response,this bit is set to 1. 0 No Error1 Resp packet Error (access R/W1TC)
  [0] HEADER — Setting of this bit means that Header Error occurs in a received packet. 0 No Error1 Header Error (access R/W1TC)
0xC8 MMC_CTLCFG_UHS2_ERR_INTR_STS_ENA 32-bit — This register is used to enable the UHS-II Error Interrupt Status register fields
  [31:27] VENDOR_SPECFIC — Setting this bit to 1 enables setting of Vendor Specific Error bit in the UHS-II Error Interrupt Status register. 0h - Status is Disabled 1h - Status is Enabled Reset Source: vbus_amod_g_rst_n
  [17] DEADLOCK_TIMEOUT — Setting this bit to 1 enables setting of Timeout for Dead lock bit in the UHS-II Error Interrupt Status register. 0 Status is Disabled1 Status is Enabled
  [16] CMD_RESP_TIMEOUT — Setting this bit to 1 enables setting of Timeout for CMD_RES bit in the UHS-II Error Interrupt Status register. 0 Status is Disabled1 Status is Enabled
  [15] ADMA2_ADMA3 — Setting this bit to 1 enables setting of ADMA2/3 Error bit in the UHS-II Error Interrupt Status register. 0 Status is Disabled1 Status is Enabled
  [8] EBSY — Setting this bit to 1 enables setting of EBSY Error bit in the UHS-II Error Interrupt Status register. 0 Status is Disabled1 Status is Enabled
  [7] UNRECOVERABLE — Setting this bit to 1 enables setting of Unrecoverable Error bit in the UHS-II Error Interrupt Status register. 0 Status is Disabled1 Status is Enabled
  [5] TID — Setting this bit to 1 enables setting of TID Error bit in the UHS-II Error Interrupt Status register. 0 Status is Disabled1 Status is Enabled
  [4] FRAMING — Setting this bit to 1 enables setting of Framing Error bit in the UHS-II Error Interrupt Status register. 0 Status is Disabled1 Status is Enabled
  [3] CRC — Setting this bit to 1 enables setting of CRC Error bit in the UHS-II Error Interrupt Status register. 0 Status is Disabled1 Status is Enabled
  [2] RETRY_EXPIRED — Setting this bit to 1 enables setting of Retry Expired bit in the UHS-II Error Interrupt Status register. 0 Status is Disabled1 Status is Enabled
  [1] RESP_PKT — Setting this bit to 1 enables setting of RES Packet Error bit in the UHS-II Error Interrupt Status register. 0 Status is Disabled1 Status is Enabled
  [0] HEADER — Setting this bit to 1 enables setting of Header Error bit in the UHS-II Error Interrupt Status Register. 0 Status is Disabled1 Status is Enabled
